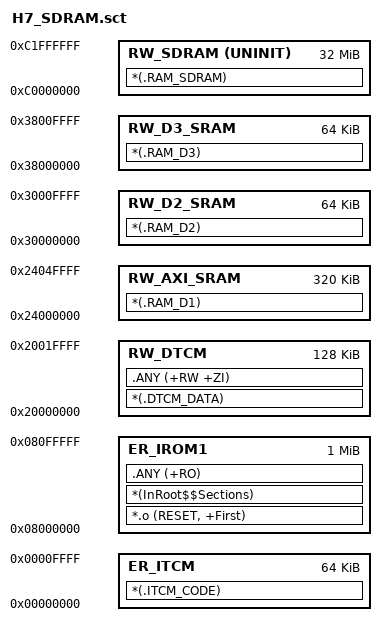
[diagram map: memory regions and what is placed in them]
LR_IROM1 0x08000000 0x00100000  {

  ER_IROM1 0x08000000 0x00100000  {
    *.o (RESET, +First)
    *(InRoot$$Sections)
    .ANY (+RO)
  }

  ER_ITCM 0x00000000 0x00010000  {
    *(.ITCM_CODE)
  }

  RW_DTCM 0x20000000 0x00020000  {
    *(.DTCM_DATA)
    .ANY (+RW +ZI)
  }

  RW_AXI_SRAM 0x24000000 0x00050000  {
    *(.RAM_D1)
  }

  RW_D2_SRAM 0x30000000 0x00010000  {
    *(.RAM_D2)
  }

  RW_D3_SRAM 0x38000000 0x00010000  {
    *(.RAM_D3)
  }

  RW_SDRAM 0xC0000000 UNINIT 0x02000000  {
    *(.RAM_SDRAM)
  }
}
